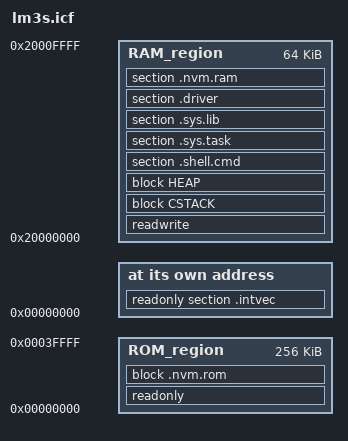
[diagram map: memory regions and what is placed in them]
/*###ICF### Section handled by ICF editor, don't touch! ****/
/*-Editor annotation file-*/
/* IcfEditorFile="$PROJ_DIR$\cortex_v1_0.xml" */
/*-Specials-*/
define symbol __ICFEDIT_intvec_start__ = 0x00000000;
/*-Memory Regions-*/
define symbol __ICFEDIT_region_ROM_start__ = 0x00000000;
define symbol __ICFEDIT_region_ROM_end__   = 0x0003FFFF;
define symbol __ICFEDIT_region_RAM_start__ = 0x20000000;
define symbol __ICFEDIT_region_RAM_end__   = 0x2000FFFF;
/*-Sizes-*/
define symbol __ICFEDIT_size_cstack__ = 0x400;
define symbol __ICFEDIT_size_heap__   = 0x800;
define symbol __ICFEDIT_size_nvm__    = 0x1000;
/**** End of ICF editor section. ###ICF###*/


define memory mem with size = 4G;
define region ROM_region   = mem:[from __ICFEDIT_region_ROM_start__   to __ICFEDIT_region_ROM_end__];
define region RAM_region   = mem:[from __ICFEDIT_region_RAM_start__   to __ICFEDIT_region_RAM_end__];

define block CSTACK    with alignment = 8, size = __ICFEDIT_size_cstack__   { };
define block HEAP      with alignment = 8, size = __ICFEDIT_size_heap__     { };

initialize by copy { readwrite };
do not initialize  { section .noinit };

place at address mem:__ICFEDIT_intvec_start__ { readonly section .intvec };

place in ROM_region   { readonly };
place in RAM_region   { readwrite,
                        block CSTACK, block HEAP };

place in RAM_region   { section .shell.cmd };
keep { section .shell.cmd };
place in RAM_region   { section .sys.task };
keep { section .sys.task };
place in RAM_region   { section .sys.lib };
keep { section .sys.lib };
place in RAM_region   { section .driver };
keep { section .driver };

/*nvm support*/
place in RAM_region   { section .nvm.ram };
keep { section .nvm.ram };
define block .nvm.rom      with alignment = 0x800, size = __ICFEDIT_size_nvm__ * 2     { };
keep { block .nvm.rom };
place in ROM_region   { block .nvm.rom };
